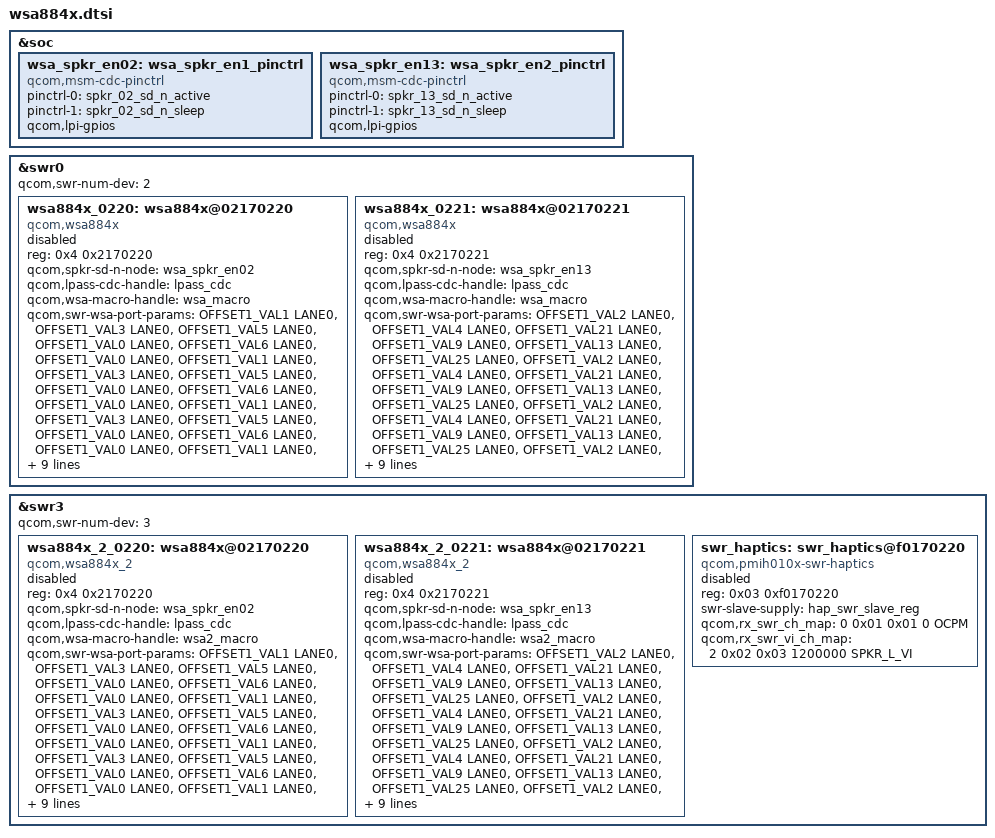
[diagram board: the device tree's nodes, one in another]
//
/* Copyright (c) Qualcomm Technologies, Inc. and/or its subsidiaries.
 * SPDX-License-Identifier: BSD-3-Clause-Clear
 */
&soc {
	wsa_spkr_en02: wsa_spkr_en1_pinctrl {
		compatible = "qcom,msm-cdc-pinctrl";
		pinctrl-names = "aud_active", "aud_sleep";
		pinctrl-0 = <&spkr_02_sd_n_active>;
		pinctrl-1 = <&spkr_02_sd_n_sleep>;
		qcom,lpi-gpios;
	};

	wsa_spkr_en13: wsa_spkr_en2_pinctrl {
		compatible = "qcom,msm-cdc-pinctrl";
		pinctrl-names = "aud_active", "aud_sleep";
		pinctrl-0 = <&spkr_13_sd_n_active>;
		pinctrl-1 = <&spkr_13_sd_n_sleep>;
		qcom,lpi-gpios;
	};

};

&swr0 {
	qcom,swr-num-dev = <2>;
	wsa884x_0220: wsa884x@02170220 {
		compatible = "qcom,wsa884x";
		status = "disabled";
		reg = <0x4 0x2170220>;
		qcom,spkr-sd-n-node = <&wsa_spkr_en02>;
		qcom,lpass-cdc-handle = <&lpass_cdc>;
		qcom,wsa-macro-handle = <&wsa_macro>;
		qcom,swr-wsa-port-params =
			<OFFSET1_VAL1 LANE0>, <OFFSET1_VAL3 LANE0>,
			<OFFSET1_VAL5 LANE0>, <OFFSET1_VAL0 LANE0>,
			<OFFSET1_VAL6 LANE0>, <OFFSET1_VAL0 LANE0>,
			<OFFSET1_VAL1 LANE0>, <OFFSET1_VAL3 LANE0>,
			<OFFSET1_VAL5 LANE0>, <OFFSET1_VAL0 LANE0>,
			<OFFSET1_VAL6 LANE0>, <OFFSET1_VAL0 LANE0>,
			<OFFSET1_VAL1 LANE0>, <OFFSET1_VAL3 LANE0>,
			<OFFSET1_VAL5 LANE0>, <OFFSET1_VAL0 LANE0>,
			<OFFSET1_VAL6 LANE0>, <OFFSET1_VAL0 LANE0>,
			<OFFSET1_VAL1 LANE0>, <OFFSET1_VAL3 LANE0>,
			<OFFSET1_VAL5 LANE0>, <OFFSET1_VAL0 LANE0>,
			<OFFSET1_VAL6 LANE0>, <OFFSET1_VAL0 LANE0>;
		cdc-vdd-1p8-supply = <&L15B>;
		qcom,cdc-vdd-1p8-voltage = <1800000 1800000>;
		qcom,cdc-vdd-1p8-current = <20000>;
		qcom,cdc-vdd-1p8-lpm-supported = <1>;
		qcom,cdc-static-supplies = "cdc-vdd-1p8";
		sound-name-prefix = "SpkrLeft";
	};

	wsa884x_0221: wsa884x@02170221 {
		compatible = "qcom,wsa884x";
		status = "disabled";
		reg = <0x4 0x2170221>;
		qcom,spkr-sd-n-node = <&wsa_spkr_en13>;
		qcom,lpass-cdc-handle = <&lpass_cdc>;
		qcom,wsa-macro-handle = <&wsa_macro>;
		qcom,swr-wsa-port-params =
			<OFFSET1_VAL2 LANE0>, <OFFSET1_VAL4 LANE0>,
			<OFFSET1_VAL21 LANE0>, <OFFSET1_VAL9 LANE0>,
			<OFFSET1_VAL13 LANE0>, <OFFSET1_VAL25 LANE0>,
			<OFFSET1_VAL2 LANE0>, <OFFSET1_VAL4 LANE0>,
			<OFFSET1_VAL21 LANE0>, <OFFSET1_VAL9 LANE0>,
			<OFFSET1_VAL13 LANE0>, <OFFSET1_VAL25 LANE0>,
			<OFFSET1_VAL2 LANE0>, <OFFSET1_VAL4 LANE0>,
			<OFFSET1_VAL21 LANE0>, <OFFSET1_VAL9 LANE0>,
			<OFFSET1_VAL13 LANE0>, <OFFSET1_VAL25 LANE0>,
			<OFFSET1_VAL2 LANE0>, <OFFSET1_VAL4 LANE0>,
			<OFFSET1_VAL21 LANE0>, <OFFSET1_VAL9 LANE0>,
			<OFFSET1_VAL13 LANE0>, <OFFSET1_VAL25 LANE0>;
		cdc-vdd-1p8-supply = <&L15B>;
		qcom,cdc-vdd-1p8-voltage = <1800000 1800000>;
		qcom,cdc-vdd-1p8-current = <20000>;
		qcom,cdc-vdd-1p8-lpm-supported = <1>;
		qcom,cdc-static-supplies = "cdc-vdd-1p8";
		sound-name-prefix = "SpkrRight";
	};


};

&swr3 {
	qcom,swr-num-dev = <3>;
	wsa884x_2_0220: wsa884x@02170220 {
		status = "disabled";
		compatible = "qcom,wsa884x_2";
		reg = <0x4 0x2170220>;
		qcom,spkr-sd-n-node = <&wsa_spkr_en02>;
		qcom,lpass-cdc-handle = <&lpass_cdc>;
		qcom,wsa-macro-handle = <&wsa2_macro>;
		qcom,swr-wsa-port-params =
			<OFFSET1_VAL1 LANE0>, <OFFSET1_VAL3 LANE0>, <OFFSET1_VAL5 LANE0>, <OFFSET1_VAL0 LANE0>, <OFFSET1_VAL6 LANE0>, <OFFSET1_VAL0 LANE0>,
			<OFFSET1_VAL1 LANE0>, <OFFSET1_VAL3 LANE0>, <OFFSET1_VAL5 LANE0>, <OFFSET1_VAL0 LANE0>, <OFFSET1_VAL6 LANE0>, <OFFSET1_VAL0 LANE0>,
			<OFFSET1_VAL1 LANE0>, <OFFSET1_VAL3 LANE0>, <OFFSET1_VAL5 LANE0>, <OFFSET1_VAL0 LANE0>, <OFFSET1_VAL6 LANE0>, <OFFSET1_VAL0 LANE0>,
			<OFFSET1_VAL1 LANE0>, <OFFSET1_VAL3 LANE0>, <OFFSET1_VAL5 LANE0>, <OFFSET1_VAL0 LANE0>, <OFFSET1_VAL6 LANE0>, <OFFSET1_VAL0 LANE0>;
		cdc-vdd-1p8-supply = <&L15B>;
		qcom,cdc-vdd-1p8-voltage = <1800000 1800000>;
		qcom,cdc-vdd-1p8-current = <20000>;
		qcom,cdc-vdd-1p8-lpm-supported = <1>;
		qcom,cdc-static-supplies = "cdc-vdd-1p8";
		sound-name-prefix = "Spkr2Left";
	};

	wsa884x_2_0221: wsa884x@02170221 {
		status = "disabled";
		compatible = "qcom,wsa884x_2";
		reg = <0x4 0x2170221>;
		qcom,spkr-sd-n-node = <&wsa_spkr_en13>;
		qcom,lpass-cdc-handle = <&lpass_cdc>;
		qcom,wsa-macro-handle = <&wsa2_macro>;
		qcom,swr-wsa-port-params =
			<OFFSET1_VAL2 LANE0>, <OFFSET1_VAL4 LANE0>, <OFFSET1_VAL21 LANE0>, <OFFSET1_VAL9 LANE0>, <OFFSET1_VAL13 LANE0>, <OFFSET1_VAL25 LANE0>,
			<OFFSET1_VAL2 LANE0>, <OFFSET1_VAL4 LANE0>, <OFFSET1_VAL21 LANE0>, <OFFSET1_VAL9 LANE0>, <OFFSET1_VAL13 LANE0>, <OFFSET1_VAL25 LANE0>,
			<OFFSET1_VAL2 LANE0>, <OFFSET1_VAL4 LANE0>, <OFFSET1_VAL21 LANE0>, <OFFSET1_VAL9 LANE0>, <OFFSET1_VAL13 LANE0>, <OFFSET1_VAL25 LANE0>,
			<OFFSET1_VAL2 LANE0>, <OFFSET1_VAL4 LANE0>, <OFFSET1_VAL21 LANE0>, <OFFSET1_VAL9 LANE0>, <OFFSET1_VAL13 LANE0>, <OFFSET1_VAL25 LANE0>;
		cdc-vdd-1p8-supply = <&L15B>;
		qcom,cdc-vdd-1p8-voltage = <1800000 1800000>;
		qcom,cdc-vdd-1p8-current = <20000>;
		qcom,cdc-vdd-1p8-lpm-supported = <1>;
		qcom,cdc-static-supplies = "cdc-vdd-1p8";
		sound-name-prefix = "Spkr2Right";
	};

	swr_haptics: swr_haptics@f0170220 {
		status = "disabled";
		compatible = "qcom,pmih010x-swr-haptics";
		reg = <0x03 0xf0170220>;
		swr-slave-supply = <&hap_swr_slave_reg>;
		qcom,rx_swr_ch_map = <0 0x01 0x01 0 OCPM>;
		qcom,rx_swr_vi_ch_map = <2 0x02 0x03 1200000 SPKR_L_VI>;
	};
};
